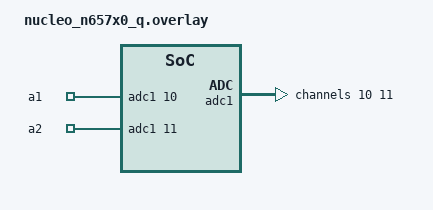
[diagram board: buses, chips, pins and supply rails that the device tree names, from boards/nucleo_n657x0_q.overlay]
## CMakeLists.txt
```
cmake_minimum_required(VERSION 3.20.0)
find_package(Zephyr REQUIRED HINTS $ENV{ZEPHYR_BASE})
project(adc)
target_sources(app PRIVATE src/main.c)
```

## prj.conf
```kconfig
CONFIG_PRINTK=y
CONFIG_SERIAL=y
CONFIG_ADC=y

CONFIG_CDC_ACM_SERIAL_INITIALIZE_AT_BOOT=y
CONFIG_USB_DEVICE_STACK_NEXT=y
```

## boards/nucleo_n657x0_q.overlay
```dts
/ {
    my_adc: zephyr,user {
        io-channels = <&adc1 10>, <&adc1 11>;
        io-channel-names = "a1", "a2";
    };

    aliases {
        my-adc = &my_adc;
    };
};

&adc1 {
    #address-cells = <1>;
    #size-cells = <0>;
    status = "okay";

    channel@a {
        reg = <10>;
        zephyr,gain = "ADC_GAIN_1";
        zephyr,reference = "ADC_REF_INTERNAL";
        zephyr,acquisition-time = <ADC_ACQ_TIME_DEFAULT>;
        zephyr,resolution = <12>;
        zephyr,vref-mv = <3300>;
    };

    channel@b {
        reg = <11>;
        zephyr,gain = "ADC_GAIN_1";
        zephyr,reference = "ADC_REF_INTERNAL";
        zephyr,acquisition-time = <ADC_ACQ_TIME_DEFAULT>;
        zephyr,resolution = <12>;
        zephyr,vref-mv = <3300>;
    };
};
```

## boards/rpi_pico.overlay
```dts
/{
    myadcs: zephyr,user{
        io-channels = <&adc 1>, <&adc 2>;
        io-channel-names = "a1", "a2" ;
    };

    aliases{
        myadc = &myadcs;  
    };
};

&adc{
    #size-cells = <0>;
    #address-cells = <1>;
    status = "okay";

    channel@1{
        reg = <1>;
        zephyr,gain = "ADC_GAIN_1";
        zephyr,reference = "ADC_REF_INTERNAL";
        zephyr,acquisition-time = <ADC_ACQ_TIME_DEFAULT>;
        zephyr,resolution = <12>;
    };

    channel@2{
        reg = <2>;
        zephyr,gain = "ADC_GAIN_1";
        zephyr,reference = "ADC_REF_INTERNAL";
        zephyr,acquisition-time = <ADC_ACQ_TIME_DEFAULT>;
        zephyr,resolution = <12>;
    };
};
```

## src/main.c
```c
#include <zephyr/kernel.h>
#include <zephyr/devicetree.h>
#include <zephyr/drivers/adc.h>

#define ADC_NODE DT_ALIAS(myadc)

static const struct adc_dt_spec adc_a1 = ADC_DT_SPEC_GET_BY_NAME(ADC_NODE, a1);
static const struct adc_dt_spec adc_a2 = ADC_DT_SPEC_GET_BY_NAME(ADC_NODE, a2);

uint16_t raw_a1[2];
uint16_t raw_a2[2];

static struct adc_sequence seq_a1 = {
    .buffer = raw_a1,
    .buffer_size = sizeof(raw_a1),
};

static struct adc_sequence seq_a2 = {
    .buffer = raw_a2,
    .buffer_size = sizeof(raw_a2),
};

int main(){

    uint32_t raw1;
    uint32_t raw2;

    adc_sequence_init_dt(&adc_a1, &seq_a1);
    adc_sequence_init_dt(&adc_a2, &seq_a2);

    while(1){

        adc_read_dt(&adc_a1, &seq_a1);
        adc_read_dt(&adc_a2, &seq_a2);

        raw1 = raw_a1[0];
        raw2 = raw_a2[0];

        printk("Raw value of a1: %d \n", (int)raw1);
        printk("Raw value of a2: %d \n", (int)raw2);

        k_msleep(500);
    }

}
```
